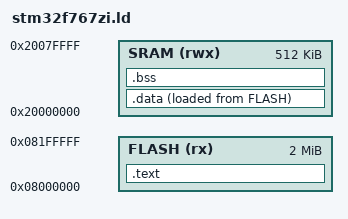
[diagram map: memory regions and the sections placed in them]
/*
 * stm32f767zi.ld — Linker script for STM32F767ZI
 *
 * FLASH: 2048K @ 0x08000000
 * SRAM:   512K @ 0x20000000
 */

MEMORY
{
    FLASH (rx)  : ORIGIN = 0x08000000, LENGTH = 2048K
    SRAM  (rwx) : ORIGIN = 0x20000000, LENGTH = 512K
}

_estack = ORIGIN(SRAM) + LENGTH(SRAM);

SECTIONS
{
    /* Vector table + code + read-only data → FLASH */
    .text :
    {
        . = ALIGN(4);
        KEEP(*(.isr_vector))
        *(.text)
        *(.text.*)
        *(.rodata)
        *(.rodata.*)
        . = ALIGN(4);
        _etext = .;
    } > FLASH

    /* Initialised data: load address in FLASH, VMA in SRAM */
    _sidata = LOADADDR(.data);
    .data :
    {
        . = ALIGN(4);
        _sdata = .;
        *(.data)
        *(.data.*)
        . = ALIGN(4);
        _edata = .;
    } > SRAM AT> FLASH

    /* Zero-initialised data → SRAM */
    .bss :
    {
        . = ALIGN(4);
        _sbss = .;
        *(.bss)
        *(.bss.*)
        *(COMMON)
        . = ALIGN(4);
        _ebss = .;
    } > SRAM

    /* Discard unwind tables (no exceptions on bare metal) */
    /DISCARD/ :
    {
        *(.ARM.exidx*)
        *(.ARM.extab*)
    }
}
